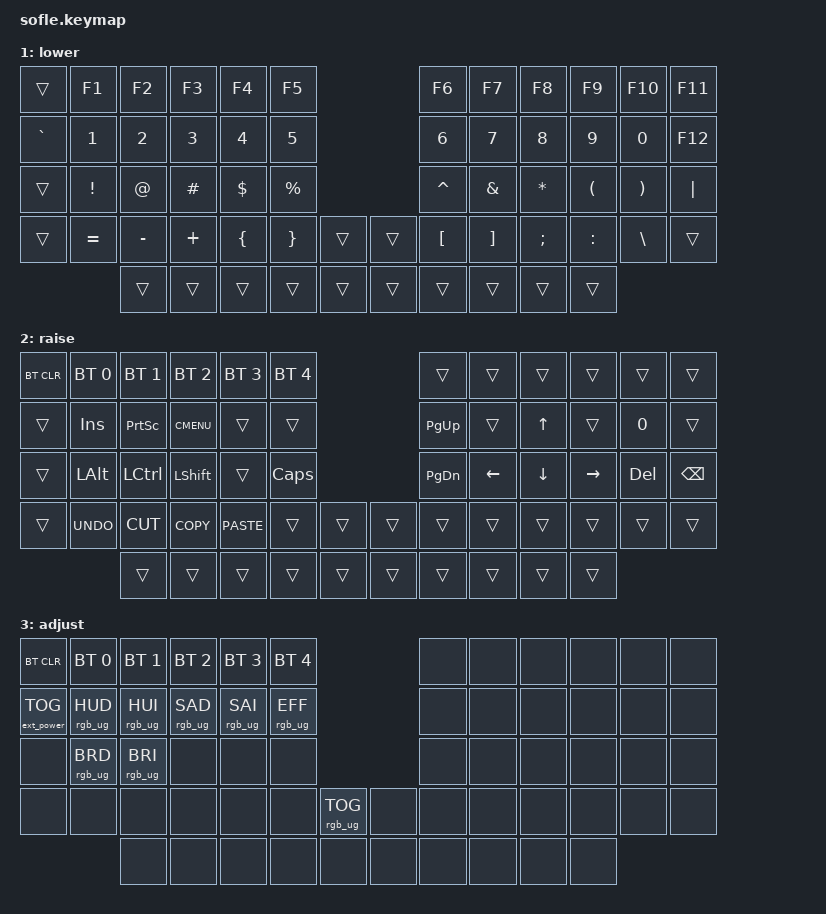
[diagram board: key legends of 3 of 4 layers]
/*
 * Copyright (c) 2020 The ZMK Contributors
 *
 * SPDX-License-Identifier: MIT
 */

#include <behaviors.dtsi>
#include <dt-bindings/zmk/keys.h>
#include <dt-bindings/zmk/bt.h>
#include <dt-bindings/zmk/rgb.h>
#include <dt-bindings/zmk/ext_power.h>
#include <dt-bindings/zmk/pointing.h>

// // Testing
// // #include <dt-bindings/zmk/mouse.h>

// #define DEFAULT 0
// #define LOWER 1
// #define RAISE 2
// #define MOUSE 3


// // This lets you define how fast the maximum speed is reached. So after 500ms the speed will be the full speed defined. In other words, it is the amount of time you need to hold a key to move the mouse before reaching the full speed.
// #define MOUSE_TIME_TO_MAX_SPEED 500 


// // This is what you need to set the mouse speed
// #define U_MOUSE_MOVE_MAX 3000



// #undef MOVE_UP
// #undef MOVE_DOWN
// #undef MOVE_LEFT
// #undef MOVE_RIGHT
// #define MOVE_UP MOVE_VERT(-U_MOUSE_MOVE_MAX)
// #define MOVE_DOWN MOVE_VERT(U_MOUSE_MOVE_MAX)
// #define MOVE_LEFT MOVE_HOR(-U_MOUSE_MOVE_MAX)
// #define MOVE_RIGHT MOVE_HOR(U_MOUSE_MOVE_MAX)

// &mmv {
//     time-to-max-speed-ms = <MOUSE_TIME_TO_MAX_SPEED>;
// };


// // This is was you need for setting the scroll speed
// #define U_MOUSE_SCROLL_MAX 20 


// #undef SCROLL_UP
// #undef SCROLL_DOWN
// #undef SCROLL_LEFT
// #undef SCROLL_RIGHT
// #define SCROLL_UP SCROLL_VERT(U_MOUSE_SCROLL_MAX)
// #define SCROLL_DOWN SCROLL_VERT(-U_MOUSE_SCROLL_MAX)
// #define SCROLL_LEFT SCROLL_HOR(-U_MOUSE_SCROLL_MAX)
// #define SCROLL_RIGHT SCROLL_HOR(U_MOUSE_SCROLL_MAX)

// // &mwh {
// //     time-to-max-speed-ms = <MOUSE_TIME_TO_MAX_SPEED>;
// // };
// // Testing


#define BASE 0
#define LOWER 1
#define RAISE 2
#define ADJUST 3

/ {

   // Activate ADJUST layer by pressing raise and lower
    conditional_layers {
        compatible = "zmk,conditional-layers";
        adjust_layer {
            if-layers = <LOWER RAISE>;
            then-layer = <ADJUST>;
        };
    };

    keymap {
        compatible = "zmk,keymap";

        default_layer {
            display-name = "default";
// ------------------------------------------------------------------------------------------------------------
// |   `   |  1  |  2  |  3   |  4   |  5   |                   |  6   |  7    |  8    |  9   |   0   |       |
// |  ESC  |  Q  |  W  |  E   |  R   |  T   |                   |  Y   |  U    |  I    |  O   |   P   | BKSPC |
// |  TAB  |  A  |  S  |  D   |  F   |  G   |                   |  H   |  J    |  K    |  L   |   ;   |   '   |
// | SHIFT |  Z  |  X  |  C   |  V   |  B   |  MUTE  |  |       |  N   |  M    |  ,    |  .   |   /   | SHIFT |
//               | GUI | ALT  | CTRL | LOWER|  ENTER |  | SPACE | RAISE| CTRL  | ALT   | GUI  |


// Swipe Up → move mouse up
// Swipe Down → move mouse down
// Swipe Left → move mouse left
// Swipe Right → move mouse right
// Tap → left click
            bindings = <
&kp GRAVE &kp N1 &kp N2   &kp N3   &kp N4    &kp N5                          &mmv MOVE_UP                      &kp N6 &kp N7    &kp N8    &kp N9   &kp N0   &none
&kp ESC   &kp Q  &kp W    &kp E    &kp R     &kp T            &mmv MOVE_LEFT   &msc MB1     &mmv MOVE_RIGHT    &kp Y  &kp U     &kp I     &kp O    &kp P    &kp BSPC
&kp TAB   &kp A  &kp S    &kp D    &kp F     &kp G                           &mmv MOVE_DOWN                    &kp H  &kp J     &kp K     &kp L    &kp SEMI &kp SQT
&kp LSHFT &kp Z  &kp X    &kp C    &kp V     &kp B      &kp C_MUTE                                  &none      &kp N  &kp M     &kp COMMA &kp DOT  &kp FSLH &kp RSHFT
                 &kp LGUI &kp LALT &kp LCTRL &mo LOWER  &kp RET                                     &kp SPACE  &mo RAISE  &kp RCTRL &kp RALT  &kp RGUI
            >;

            sensor-bindings = <&inc_dec_kp C_VOL_UP C_VOL_DN &inc_dec_kp PG_UP PG_DN>;
        };

        lower_layer {
            display-name = "lower";
// TODO: Some binds are waiting for shifted keycode support.
// ------------------------------------------------------------------------------------------------------------
// |       |  F1 |  F2 |  F3  |  F4  |  F5  |                   |  F6  |  F7   |  F8   |  F9  |  F10  |  F11  |
// |   `   |  1  |  2  |  3   |  4   |  5   |                   |  6   |  7    |  8    |  9   |   0   |  F12  |
// |       |  !  |  @  |  #   |  $   |  %   |                   |  ^   |  &    |  *    |  (   |   )   |   |   |
// |       |  =  |  -  |  +   |  {   |  }   |        |  |       |  [   |  ]    |  ;    |  :   |   \   |       |
//               |     |      |      |      |        |  |       |      |       |       |      |
            bindings = <
&trans    &kp F1    &kp F2    &kp F3      &kp F4    &kp F5                       &kp F6    &kp F7   &kp F8    &kp F9    &kp F10   &kp F11
&kp GRAVE &kp N1    &kp N2    &kp N3      &kp N4    &kp N5                       &kp N6    &kp N7   &kp N8    &kp N9    &kp N0    &kp F12
&trans    &kp EXCL  &kp AT    &kp HASH    &kp DLLR  &kp PRCNT                    &kp CARET &kp AMPS &kp ASTRK &kp LPAR  &kp RPAR  &kp PIPE
&trans    &kp EQUAL &kp MINUS &kp PLUS    &kp LBRC  &kp RBRC   &trans    &trans  &kp LBKT  &kp RBKT &kp SEMI  &kp COLON &kp BSLH  &trans
                    &trans    &trans      &trans    &trans     &trans    &trans  &trans    &trans   &trans    &trans
            >;

            sensor-bindings = <&inc_dec_kp C_VOL_UP C_VOL_DN &inc_dec_kp PG_UP PG_DN>;
            // bindings = <
            //     &mmv MOVE_UP   
            //     &mmv MOVE_DOWN 
            //     &mmv MOVE_LEFT 
            //     &mmv MOVE_RIGHT
            //     &msc MB1    
            //      >;
        };

        raise_layer {
            display-name = "raise";
// ------------------------------------------------------------------------------------------------------------
// | BTCLR | BT1  | BT2  |  BT3  |  BT4  |  BT5 |                |      |      |       |      |       |       |
// |       | INS  | PSCR | GUI   |       |      |                | PGUP |      |   ^   |      |       |       |
// |       | ALT  | CTRL | SHIFT |       | CAPS |                | PGDN |   <- |   v   |  ->  |  DEL  | BKSPC |
// |       | UNDO | CUT  | COPY  | PASTE |      |      |  |      |      |      |       |      |       |       |
//                |      |       |       |      |      |  |      |      |      |       |      |
            bindings = <
&bt BT_CLR &bt BT_SEL 0 &bt BT_SEL 1 &bt BT_SEL 2 &bt BT_SEL 3 &bt BT_SEL 4                  &trans    &trans    &trans   &trans    &trans  &trans
&trans     &kp INS      &kp PSCRN    &kp K_CMENU  &trans       &trans                        &kp PG_UP &trans    &kp UP   &trans    &kp N0  &trans
&trans     &kp LALT     &kp LCTRL    &kp LSHFT    &trans       &kp CLCK                      &kp PG_DN &kp LEFT  &kp DOWN &kp RIGHT &kp DEL &kp BSPC
&trans     &kp K_UNDO   &kp K_CUT    &kp K_COPY   &kp K_PASTE  &trans        &trans  &trans  &trans    &trans    &trans   &trans    &trans  &trans
                        &trans       &trans       &trans       &trans        &trans  &trans  &trans    &trans    &trans   &trans
            >;

            sensor-bindings = <&inc_dec_kp C_VOL_UP C_VOL_DN &inc_dec_kp PG_UP PG_DN>;
            // bindings = <
            //     &mmv MOVE_UP
            //     &mmv MOVE_DOWN
            //     &mmv MOVE_LEFT
            //     &mmv MOVE_RIGHT
            //     &msc MB1
            //      >;
        };

        adjust_layer {
// ----------------------------------------------------------------------------------------------------------------------------
// | BTCLR  |  BT1    |  BT2    |   BT3   |   BT4   |   BT5   |                  |      |      |       |      |       |       |
// | EXTPWR | RGB_HUD | RGB_HUI | RGB_SAD | RGB_SAI | RGB_EFF |                  |      |      |       |      |       |       |
// |        | RGB_BRD | RGB_BRI |         |         |         |                  |      |      |       |      |       |       |
// |        |         |         |         |         |         | RGB_TOG | |      |      |      |       |      |       |       |
//                    |         |         |         |         |         | |      |      |      |       |      |
            display-name = "adjust";
            bindings = <
&bt BT_CLR        &bt BT_SEL 0    &bt BT_SEL 1    &bt BT_SEL 2    &bt BT_SEL 3    &bt BT_SEL 4                            &none &none &none &none &none &none
&ext_power EP_TOG &rgb_ug RGB_HUD &rgb_ug RGB_HUI &rgb_ug RGB_SAD &rgb_ug RGB_SAI &rgb_ug RGB_EFF                         &none &none &none &none &none &none
&none             &rgb_ug RGB_BRD &rgb_ug RGB_BRI &none           &none           &none                                   &none &none &none &none &none &none
&none             &none           &none           &none           &none           &none            &rgb_ug RGB_TOG &none  &none &none &none &none &none &none
                                  &none           &none           &none           &none            &none           &none  &none &none &none &none
            >;

            sensor-bindings = <&inc_dec_kp C_VOL_UP C_VOL_DN &inc_dec_kp PG_UP PG_DN>;
            // bindings = <
            //     &mmv MOVE_UP
            //     &mmv MOVE_DOWN
            //     &mmv MOVE_LEFT
            //     &mmv MOVE_RIGHT
            //     &msc MB1
            //      >;
        };

    };
};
